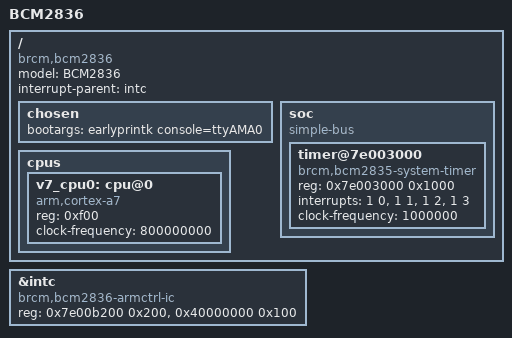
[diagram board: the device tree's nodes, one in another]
#include <dt-bindings/pinctrl/bcm2835.h>
#include "skeleton.dtsi"
#include "bcm283x-common.dtsi"

/ {
	compatible = "brcm,bcm2836";
	model = "BCM2836";
	interrupt-parent = <&intc>;

	chosen {
		bootargs = "earlyprintk console=ttyAMA0";
	};

	soc {
		compatible = "simple-bus";
		#address-cells = <1>;
		#size-cells = <1>;
		ranges = <0x7e000000 0x3f000000 0x01000000>;

		timer@7e003000 {
			compatible = "brcm,bcm2835-system-timer";
			reg = <0x7e003000 0x1000>;
			interrupts = <1 0>, <1 1>, <1 2>, <1 3>;
			clock-frequency = <1000000>;
		};
	};

	cpus: cpus {
		#address-cells = <1>;
		#size-cells = <0>;

		v7_cpu0: cpu@0 {
			device_type = "cpu";
			compatible = "arm,cortex-a7";
			reg = <0xf00>;
			clock-frequency = <800000000>;
		};
	};

	__overrides__ {
		arm_freq = <&v7_cpu0>, "clock-frequency:0";
	};
};

&intc {
	compatible = "brcm,bcm2836-armctrl-ic";
	reg = <0x7e00b200 0x200>, <0x40000000 0x100>;
};
